# EMBSIMTEST register map
File version: 1.0
EmbSim's register-file test device
Registers are 32-bit, read-write, reset 0x0 unless marked. A register's access mark holds for its fields unless they carry their own. Offsets are from the block's base; lines under a group give offsets from that group; [hi:lo] are bit positions; {n}, {i} and the like mark numbered series; 'fields as' and 'values as' point back to an identical list; <NAME> marks a mode.

## Memory map
0x40010000 ACC size 0x100
0x40011000 MWV
0x40012000 ARR
0x40013000 ARR2

## Interrupts
3 ACC_IRQ (ACC)

## ACC
Base 0x40010000
0x00 RW reset 0x12345678
0x04 RO ro reset 0xA5A5A5A5
0x08 WO wo reset 0x77
0x0C ONCE write-once
0x10 RONCE rw-once reset 0x11
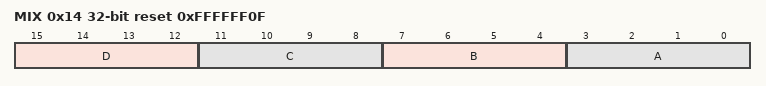
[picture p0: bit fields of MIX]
0x14 MIX reset 0xFFFFFF0F
  [15:12] D, [11:8] C wo, [7:4] B ro, [3:0] A
0x18 B8 8-bit reset 0x5A
0x19 B8B 8-bit
0x1A H16 16-bit reset 0xBEEF
0x20 LAST

## MWV
Base 0x40011000
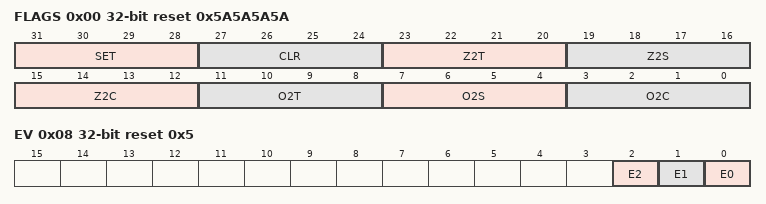
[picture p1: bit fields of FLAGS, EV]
0x00 FLAGS reset 0x5A5A5A5A
  [31:28] SET write-sets, [27:24] CLR write-clears, [23:20] Z2T write-0-toggles, [19:16] Z2S write-0-sets, [15:12] Z2C write-0-clears, [11:8] O2T write-1-toggles, [7:4] O2S write-1-sets, [3:0] O2C write-1-clears
0x04 W1C reset 0xFF write-1-clears
0x08 EV reset 0x5
  [2] E2 read-modifies, [1] E1 read-sets, [0] E0 read-clears
0x0C RC reset 0xCAFE read-clears
0x10 MODE
  [1:0] SEL
    0=Off; 1=Slow; 2=Fast

## ARR
Base 0x40012000
Same registers: ARR2 0x40013000
{0x0+0x10*i} CH[{i}] (i=0..2) group
  0x00 CTRL reset 0x100
  0x04 DATA reset 0x7
  0x08 STAT ro reset 0x2
0x40 R{x} (x=A,B,C,D; step 0x4) reset 0xAA
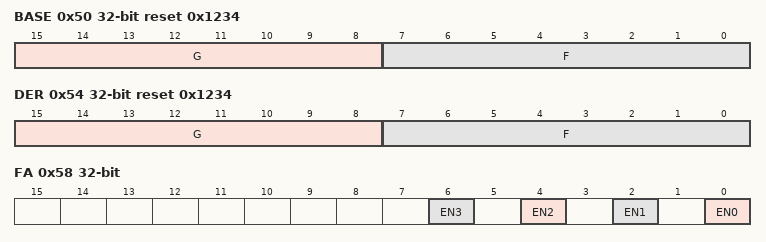
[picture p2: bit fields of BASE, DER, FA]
0x50 BASE reset 0x1234
  [15:8] G, [7:0] F write-1-clears
0x54 DER reset 0x1234
  [15:8] G, [7:0] F write-1-clears
0x58 FA
  [2n] EN{n} (n=0..3)
